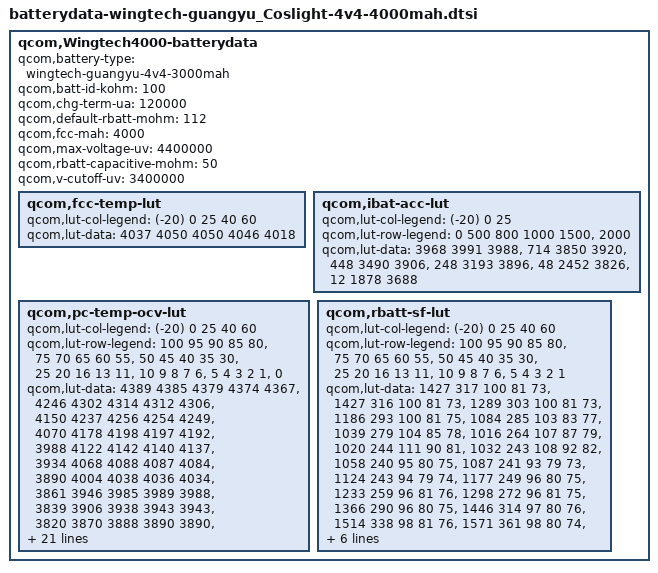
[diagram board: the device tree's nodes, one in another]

qcom,Wingtech4000-batterydata {
	qcom,battery-type = "wingtech-guangyu-4v4-3000mah";
	qcom,batt-id-kohm = <100>;
	qcom,chg-term-ua = <120000>;
	qcom,default-rbatt-mohm = <112>;
	qcom,fcc-mah = <4000>;
	qcom,max-voltage-uv = <4400000>;
	qcom,rbatt-capacitive-mohm = <50>;
	qcom,v-cutoff-uv = <3400000>;

	qcom,fcc-temp-lut {
		qcom,lut-col-legend = <(-20) 0 25 40 60>;
		qcom,lut-data = <4037 4050 4050 4046 4018>;
	};

	qcom,ibat-acc-lut {
		qcom,lut-col-legend = <(-20) 0 25>;
		qcom,lut-row-legend = <0 500 800 1000 1500>,
				<2000>;
		qcom,lut-data = <3968 3991 3988>,
				<714 3850 3920>,
				<448 3490 3906>,
				<248 3193 3896>,
				<48 2452 3826>,
				<12 1878 3688>;
	};

	qcom,pc-temp-ocv-lut {
		qcom,lut-col-legend = <(-20) 0 25 40 60>;
		qcom,lut-row-legend = <100 95 90 85 80>,
				<75 70 65 60 55>,
				<50 45 40 35 30>,
				<25 20 16 13 11>,
				<10 9 8 7 6>,
				<5 4 3 2 1>,
				<0>;
		qcom,lut-data = <4389 4385 4379 4374 4367>,
				<4246 4302 4314 4312 4306>,
				<4150 4237 4256 4254 4249>,
				<4070 4178 4198 4197 4192>,
				<3988 4122 4142 4140 4137>,
				<3934 4068 4088 4087 4084>,
				<3890 4004 4038 4036 4034>,
				<3861 3946 3985 3989 3988>,
				<3839 3906 3938 3943 3943>,
				<3820 3870 3888 3890 3890>,
				<3804 3840 3854 3854 3854>,
				<3788 3814 3828 3828 3828>,
				<3773 3794 3806 3806 3806>,
				<3756 3778 3786 3788 3786>,
				<3739 3766 3769 3768 3766>,
				<3720 3750 3753 3747 3736>,
				<3699 3730 3735 3726 3714>,
				<3678 3712 3714 3706 3694>,
				<3660 3696 3694 3686 3674>,
				<3646 3688 3686 3680 3668>,
				<3639 3686 3684 3678 3667>,
				<3628 3680 3682 3676 3665>,
				<3616 3676 3680 3674 3662>,
				<3602 3670 3676 3670 3658>,
				<3584 3659 3668 3661 3649>,
				<3562 3640 3650 3640 3626>,
				<3535 3606 3609 3596 3584>,
				<3496 3554 3550 3536 3526>,
				<3434 3475 3466 3451 3444>,
				<3316 3337 3324 3309 3312>,
				<3000 3000 3000 3000 3000>;
	};

	qcom,rbatt-sf-lut {
		qcom,lut-col-legend = <(-20) 0 25 40 60>;
		qcom,lut-row-legend = <100 95 90 85 80>,
				<75 70 65 60 55>,
				<50 45 40 35 30>,
				<25 20 16 13 11>,
				<10 9 8 7 6>,
				<5 4 3 2 1>;
		qcom,lut-data = <1427 317 100 81 73>,
				<1427 316 100 81 73>,
				<1289 303 100 81 73>,
				<1186 293 100 81 75>,
				<1084 285 103 83 77>,
				<1039 279 104 85 78>,
				<1016 264 107 87 79>,
				<1020 244 111 90 81>,
				<1032 243 108 92 82>,
				<1058 240 95 80 75>,
				<1087 241 93 79 73>,
				<1124 243 94 79 74>,
				<1177 249 96 80 75>,
				<1233 259 96 81 76>,
				<1298 272 96 81 75>,
				<1366 290 96 80 75>,
				<1446 314 97 80 76>,
				<1514 338 98 81 76>,
				<1571 361 98 80 74>,
				<1569 373 99 80 75>,
				<1587 387 100 82 77>,
				<1638 400 102 84 79>,
				<1732 417 105 88 82>,
				<1883 436 110 91 85>,
				<2069 461 113 93 86>,
				<2304 480 113 90 82>,
				<2620 505 108 86 79>,
				<3055 536 111 88 79>,
				<3730 584 115 90 82>,
				<5181 704 141 120 91>;
	};
};
